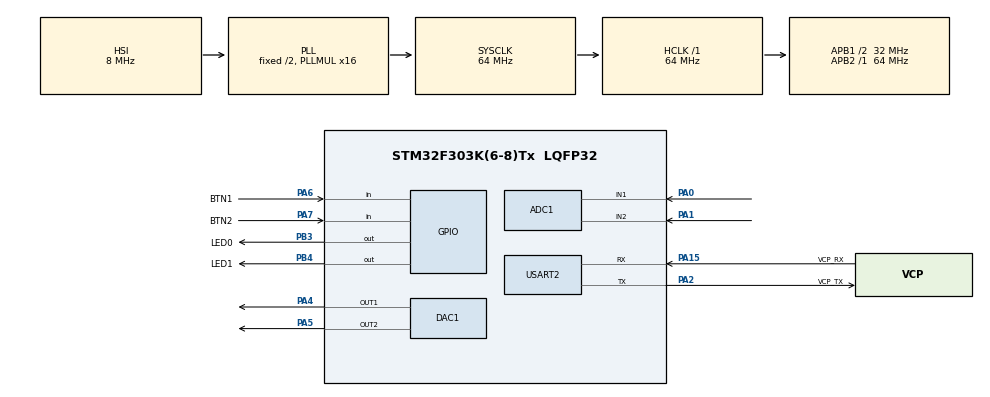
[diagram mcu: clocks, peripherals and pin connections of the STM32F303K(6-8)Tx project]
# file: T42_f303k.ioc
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ADC1.Channel-0\#ChannelRegularConversion=ADC_CHANNEL_1
ADC1.Channel-1\#ChannelRegularConversion=ADC_CHANNEL_2
ADC1.ClockPrescaler=ADC_CLOCK_SYNC_PCLK_DIV4
ADC1.ContinuousConvMode=DISABLE
ADC1.DMAContinuousRequests=ENABLE
ADC1.EOCSelection=ADC_EOC_SEQ_CONV
ADC1.ExternalTrigConv=ADC_EXTERNALTRIGCONV_T6_TRGO
ADC1.NbrOfConversion=2
ADC1.NbrOfConversionFlag=1
ADC1.Offset-0\#ChannelRegularConversion=0
ADC1.Offset-1\#ChannelRegularConversion=0
ADC1.OffsetNumber-0\#ChannelRegularConversion=ADC_OFFSET_NONE
ADC1.OffsetNumber-1\#ChannelRegularConversion=ADC_OFFSET_NONE
ADC1.Rank-0\#ChannelRegularConversion=1
ADC1.Rank-1\#ChannelRegularConversion=2
ADC1.SamplingTime-0\#ChannelRegularConversion=ADC_SAMPLETIME_61CYCLES_5
ADC1.SamplingTime-1\#ChannelRegularConversion=ADC_SAMPLETIME_61CYCLES_5
ADC1.master=1
DAC1.DAC_Trigger=DAC_TRIGGER_T2_TRGO
DAC1.DAC_Trigger2=DAC_TRIGGER_T2_TRGO
Dma.ADC1.0.Direction=DMA_PERIPH_TO_MEMORY
Dma.ADC1.0.Instance=DMA1_Channel1
Dma.ADC1.0.MemDataAlignment=DMA_MDATAALIGN_WORD
Dma.ADC1.0.MemInc=DMA_MINC_ENABLE
Dma.ADC1.0.Mode=DMA_CIRCULAR
Dma.ADC1.0.PeriphDataAlignment=DMA_PDATAALIGN_WORD
Dma.ADC1.0.PeriphInc=DMA_PINC_DISABLE
Dma.ADC1.0.Priority=DMA_PRIORITY_LOW
Dma.DAC1_CH1.1.Direction=DMA_MEMORY_TO_PERIPH
Dma.DAC1_CH1.1.Instance=DMA1_Channel3
Dma.DAC1_CH1.1.MemDataAlignment=DMA_MDATAALIGN_HALFWORD
Dma.DAC1_CH1.1.MemInc=DMA_MINC_ENABLE
Dma.DAC1_CH1.1.Mode=DMA_CIRCULAR
Dma.DAC1_CH1.1.PeriphDataAlignment=DMA_PDATAALIGN_WORD
Dma.DAC1_CH1.1.PeriphInc=DMA_PINC_DISABLE
Dma.DAC1_CH1.1.Priority=DMA_PRIORITY_MEDIUM
Dma.DAC1_CH2.2.Direction=DMA_MEMORY_TO_PERIPH
Dma.DAC1_CH2.2.Instance=DMA1_Channel4
Dma.DAC1_CH2.2.MemDataAlignment=DMA_MDATAALIGN_HALFWORD
Dma.DAC1_CH2.2.MemInc=DMA_MINC_ENABLE
Dma.DAC1_CH2.2.Mode=DMA_CIRCULAR
Dma.DAC1_CH2.2.PeriphDataAlignment=DMA_PDATAALIGN_WORD
Dma.DAC1_CH2.2.PeriphInc=DMA_PINC_DISABLE
Dma.DAC1_CH2.2.Priority=DMA_PRIORITY_MEDIUM
Dma.Request0=ADC1
Dma.Request1=DAC1_CH1
Dma.Request2=DAC1_CH2
Mcu.Family=STM32F3
Mcu.Name=STM32F303K(6-8)Tx
Mcu.Package=LQFP32
NVIC.DMA1_Channel1_IRQn=true\:4\:0\:true\:false\:true\:false\:true\:true
NVIC.DMA1_Channel3_IRQn=true\:0\:0\:false\:false\:true\:false\:true\:true
NVIC.DMA1_Channel4_IRQn=true\:0\:0\:false\:false\:true\:false\:true\:true
NVIC.PriorityGroup=NVIC_PRIORITYGROUP_4
NVIC.TIM2_IRQn=true\:0\:0\:false\:false\:true\:true\:true\:true
NVIC.TIM6_DAC1_IRQn=true\:7\:0\:true\:false\:true\:true\:true\:true
NVIC.TIM7_DAC2_IRQn=true\:11\:0\:true\:false\:true\:true\:true\:true
PA0.Mode=IN1-Single-Ended
PA0.Signal=ADC1_IN1
PA1.Mode=IN2-Single-Ended
PA1.Signal=ADC1_IN2
PA13.GPIO_Label=SWDIO
PA13.Mode=Serial_Wire
PA13.Signal=SYS_JTMS-SWDIO
PA14.GPIO_Label=SWCLK
PA14.Mode=Serial_Wire
PA14.Signal=SYS_JTCK-SWCLK
PA15.GPIO_Label=VCP_RX
PA15.Mode=Asynchronous
PA15.Signal=USART2_RX
PA2.GPIO_Label=VCP_TX
PA2.Mode=Asynchronous
PA2.Signal=USART2_TX
PA4.Signal=COMP_DAC11_group
PA5.Signal=COMP_DAC12_group
PA6.GPIO_Label=BTN1
PA6.GPIO_PuPd=GPIO_PULLUP
PA6.Signal=GPIO_Input
PA7.GPIO_Label=BTN2
PA7.GPIO_PuPd=GPIO_PULLUP
PA7.Signal=GPIO_Input
PB3.GPIO_Label=LED0
PB3.Signal=GPIO_Output
PB4.GPIO_Label=LED1
PB4.Signal=GPIO_Output
PF0\ /\ OSC_IN.GPIO_Label=MCO
PF0\ /\ OSC_IN.Mode=HSE-External-Clock-Source
PF0\ /\ OSC_IN.Signal=RCC_OSC_IN
ProjectManager.HeapSize=0x200
ProjectManager.StackSize=0x400
ProjectManager.TargetToolchain=STM32CubeIDE
RCC.AHBFreq_Value=64000000
RCC.APB1CLKDivider=RCC_HCLK_DIV2
RCC.APB1Freq_Value=32000000
RCC.APB1TimFreq_Value=64000000
RCC.APB2Freq_Value=64000000
RCC.APB2TimFreq_Value=64000000
RCC.CortexFreq_Value=64000000
RCC.HCLKFreq_Value=64000000
RCC.HSE_VALUE=8000000
RCC.HSI_VALUE=8000000
RCC.PLLMUL=RCC_PLL_MUL16
RCC.RCC_PLLsource_Clock_Source_FROM_HSE=RCC_HSE_PREDIV_DIV2
RCC.SYSCLKFreq_VALUE=64000000
RCC.SYSCLKSourceVirtual=RCC_SYSCLKSOURCE_PLLCLK
SH.COMP_DAC11_group.0=DAC1_OUT1,DAC_OUT1
SH.COMP_DAC12_group.0=DAC1_OUT2,DAC_OUT2
TIM2.Period=64
TIM2.Prescaler=1
TIM2.TIM_MasterOutputTrigger=TIM_TRGO_UPDATE
TIM3.Period=4096
TIM6.Period=600
TIM6.Prescaler=319
TIM6.TIM_MasterOutputTrigger=TIM_TRGO_UPDATE
TIM7.Period=600
TIM7.Prescaler=319 
USART2.StopBits=STOPBITS_1
USART2.VirtualMode-Asynchronous=VM_ASYNC
VP_TIM2_VS_ClockSourceINT.Mode=Internal
VP_TIM3_VS_ClockSourceITR.Mode=TriggerSource_ITR0
VP_TIM3_VS_ControllerModeTrigger.Mode=Trigger Mode
VP_TIM6_VS_ClockSourceINT.Mode=Enable_Timer
VP_TIM7_VS_ClockSourceINT.Mode=Enable_Timer
board=NUCLEO-F303K8

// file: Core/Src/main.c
/* USER CODE BEGIN Header */
/**
  ******************************************************************************
  * @file           : main.c
  * @brief          : Main program body
  ******************************************************************************
  * @attention
  *
  * Copyright (c) 2026 STMicroelectronics.
  * All rights reserved.
  *
  * This software is licensed under terms that can be found in the LICENSE file
  * in the root directory of this software component.
  * If no LICENSE file comes with this software, it is provided AS-IS.
  *
  ******************************************************************************
  */
/* USER CODE END Header */
#include "main.h"

/* USER CODE BEGIN Includes */
#include "t42.h"
/* USER CODE END Includes */

ADC_HandleTypeDef hadc1;
DMA_HandleTypeDef hdma_adc1;

DAC_HandleTypeDef hdac1;
DMA_HandleTypeDef hdma_dac1_ch1;
DMA_HandleTypeDef hdma_dac1_ch2;

TIM_HandleTypeDef htim2;
TIM_HandleTypeDef htim3;
TIM_HandleTypeDef htim6;
TIM_HandleTypeDef htim7;

UART_HandleTypeDef huart2;

void SystemClock_Config(void);
static void MX_GPIO_Init(void);
static void MX_DMA_Init(void);
static void MX_USART2_UART_Init(void);
static void MX_ADC1_Init(void);
static void MX_DAC1_Init(void);
static void MX_TIM2_Init(void);
static void MX_TIM3_Init(void);
static void MX_TIM6_Init(void);
static void MX_TIM7_Init(void);

int main(void)
{

  /* MCU Configuration--------------------------------------------------------*/

  /* Reset of all peripherals, Initializes the Flash interface and the Systick. */
  HAL_Init();

  /* Configure the system clock */
  SystemClock_Config();

  /* Initialize all configured peripherals */
  MX_GPIO_Init();
  MX_DMA_Init();
  MX_USART2_UART_Init();
  MX_ADC1_Init();
  MX_DAC1_Init();
  MX_TIM2_Init();
  MX_TIM3_Init();
  MX_TIM6_Init();
  MX_TIM7_Init();
  /* USER CODE BEGIN 2 */
  setupGame();
  /* USER CODE END 2 */

  /* Infinite loop */
  /* USER CODE BEGIN WHILE */
  while (1)
  {
	  updateGame();
    /* USER CODE END WHILE */

  }
}

void SystemClock_Config(void)
{
  RCC_OscInitTypeDef RCC_OscInitStruct = {0};
  RCC_ClkInitTypeDef RCC_ClkInitStruct = {0};

  /** Initializes the RCC Oscillators according to the specified parameters
  * in the RCC_OscInitTypeDef structure.
  */
  RCC_OscInitStruct.OscillatorType = RCC_OSCILLATORTYPE_HSI;
  RCC_OscInitStruct.HSIState = RCC_HSI_ON;
  RCC_OscInitStruct.HSICalibrationValue = RCC_HSICALIBRATION_DEFAULT;
  RCC_OscInitStruct.PLL.PLLState = RCC_PLL_ON;
  RCC_OscInitStruct.PLL.PLLSource = RCC_PLLSOURCE_HSI;
  RCC_OscInitStruct.PLL.PLLMUL = RCC_PLL_MUL16;
  if (HAL_RCC_OscConfig(&RCC_OscInitStruct) != HAL_OK)
  {
    Error_Handler();
  }

  /** Initializes the CPU, AHB and APB buses clocks
  */
  RCC_ClkInitStruct.ClockType = RCC_CLOCKTYPE_HCLK|RCC_CLOCKTYPE_SYSCLK
                              |RCC_CLOCKTYPE_PCLK1|RCC_CLOCKTYPE_PCLK2;
  RCC_ClkInitStruct.SYSCLKSource = RCC_SYSCLKSOURCE_PLLCLK;
  RCC_ClkInitStruct.AHBCLKDivider = RCC_SYSCLK_DIV1;
  RCC_ClkInitStruct.APB1CLKDivider = RCC_HCLK_DIV2;
  RCC_ClkInitStruct.APB2CLKDivider = RCC_HCLK_DIV1;

  if (HAL_RCC_ClockConfig(&RCC_ClkInitStruct, FLASH_LATENCY_2) != HAL_OK)
  {
    Error_Handler();
  }
}

static void MX_ADC1_Init(void)
{

  ADC_MultiModeTypeDef multimode = {0};
  ADC_ChannelConfTypeDef sConfig = {0};

  /** Common config
  */
  hadc1.Instance = ADC1;
  hadc1.Init.ClockPrescaler = ADC_CLOCK_SYNC_PCLK_DIV4;
  hadc1.Init.Resolution = ADC_RESOLUTION_12B;
  hadc1.Init.ScanConvMode = ADC_SCAN_ENABLE;
  hadc1.Init.ContinuousConvMode = DISABLE;
  hadc1.Init.DiscontinuousConvMode = DISABLE;
  hadc1.Init.ExternalTrigConvEdge = ADC_EXTERNALTRIGCONVEDGE_RISING;
  hadc1.Init.ExternalTrigConv = ADC_EXTERNALTRIGCONV_T6_TRGO;
  hadc1.Init.DataAlign = ADC_DATAALIGN_RIGHT;
  hadc1.Init.NbrOfConversion = 2;
  hadc1.Init.DMAContinuousRequests = ENABLE;
  hadc1.Init.EOCSelection = ADC_EOC_SEQ_CONV;
  hadc1.Init.LowPowerAutoWait = DISABLE;
  hadc1.Init.Overrun = ADC_OVR_DATA_OVERWRITTEN;
  if (HAL_ADC_Init(&hadc1) != HAL_OK)
  {
    Error_Handler();
  }

  /** Configure the ADC multi-mode
  */
  multimode.Mode = ADC_MODE_INDEPENDENT;
  if (HAL_ADCEx_MultiModeConfigChannel(&hadc1, &multimode) != HAL_OK)
  {
    Error_Handler();
  }

  /** Configure Regular Channel
  */
  sConfig.Channel = ADC_CHANNEL_1;
  sConfig.Rank = ADC_REGULAR_RANK_1;
  sConfig.SingleDiff = ADC_SINGLE_ENDED;
  sConfig.SamplingTime = ADC_SAMPLETIME_61CYCLES_5;
  sConfig.OffsetNumber = ADC_OFFSET_NONE;
  sConfig.Offset = 0;
  if (HAL_ADC_ConfigChannel(&hadc1, &sConfig) != HAL_OK)
  {
    Error_Handler();
  }

  /** Configure Regular Channel
  */
  sConfig.Channel = ADC_CHANNEL_2;
  sConfig.Rank = ADC_REGULAR_RANK_2;
  if (HAL_ADC_ConfigChannel(&hadc1, &sConfig) != HAL_OK)
  {
    Error_Handler();
  }

}

static void MX_DAC1_Init(void)
{

  DAC_ChannelConfTypeDef sConfig = {0};

  /** DAC Initialization
  */
  hdac1.Instance = DAC1;
  if (HAL_DAC_Init(&hdac1) != HAL_OK)
  {
    Error_Handler();
  }

  /** DAC channel OUT1 config
  */
  sConfig.DAC_Trigger = DAC_TRIGGER_T2_TRGO;
  sConfig.DAC_OutputBuffer = DAC_OUTPUTBUFFER_ENABLE;
  if (HAL_DAC_ConfigChannel(&hdac1, &sConfig, DAC_CHANNEL_1) != HAL_OK)
  {
    Error_Handler();
  }

  /** DAC channel OUT2 config
  */
  sConfig.DAC_OutputSwitch = DAC_OUTPUTSWITCH_ENABLE;
  if (HAL_DAC_ConfigChannel(&hdac1, &sConfig, DAC_CHANNEL_2) != HAL_OK)
  {
    Error_Handler();
  }

}

static void MX_TIM2_Init(void)
{

  TIM_ClockConfigTypeDef sClockSourceConfig = {0};
  TIM_MasterConfigTypeDef sMasterConfig = {0};

  htim2.Instance = TIM2;
  htim2.Init.Prescaler = 1;
  htim2.Init.CounterMode = TIM_COUNTERMODE_UP;
  htim2.Init.Period = 64;
  htim2.Init.ClockDivision = TIM_CLOCKDIVISION_DIV1;
  htim2.Init.AutoReloadPreload = TIM_AUTORELOAD_PRELOAD_DISABLE;
  if (HAL_TIM_Base_Init(&htim2) != HAL_OK)
  {
    Error_Handler();
  }
  sClockSourceConfig.ClockSource = TIM_CLOCKSOURCE_INTERNAL;
  if (HAL_TIM_ConfigClockSource(&htim2, &sClockSourceConfig) != HAL_OK)
  {
    Error_Handler();
  }
  sMasterConfig.MasterOutputTrigger = TIM_TRGO_UPDATE;
  sMasterConfig.MasterSlaveMode = TIM_MASTERSLAVEMODE_DISABLE;
  if (HAL_TIMEx_MasterConfigSynchronization(&htim2, &sMasterConfig) != HAL_OK)
  {
    Error_Handler();
  }

}

static void MX_TIM3_Init(void)
{

  TIM_SlaveConfigTypeDef sSlaveConfig = {0};
  TIM_MasterConfigTypeDef sMasterConfig = {0};

  htim3.Instance = TIM3;
  htim3.Init.Prescaler = 0;
  htim3.Init.CounterMode = TIM_COUNTERMODE_UP;
  htim3.Init.Period = 4096;
  htim3.Init.ClockDivision = TIM_CLOCKDIVISION_DIV1;
  htim3.Init.AutoReloadPreload = TIM_AUTORELOAD_PRELOAD_DISABLE;
  if (HAL_TIM_Base_Init(&htim3) != HAL_OK)
  {
    Error_Handler();
  }
  sSlaveConfig.SlaveMode = TIM_SLAVEMODE_TRIGGER;
  sSlaveConfig.InputTrigger = TIM_TS_ITR0;
  if (HAL_TIM_SlaveConfigSynchro(&htim3, &sSlaveConfig) != HAL_OK)
  {
    Error_Handler();
  }
  sMasterConfig.MasterOutputTrigger = TIM_TRGO_RESET;
  sMasterConfig.MasterSlaveMode = TIM_MASTERSLAVEMODE_DISABLE;
  if (HAL_TIMEx_MasterConfigSynchronization(&htim3, &sMasterConfig) != HAL_OK)
  {
    Error_Handler();
  }

}

static void MX_TIM6_Init(void)
{

  TIM_MasterConfigTypeDef sMasterConfig = {0};

  htim6.Instance = TIM6;
  htim6.Init.Prescaler = 319;
  htim6.Init.CounterMode = TIM_COUNTERMODE_UP;
  htim6.Init.Period = 600;
  htim6.Init.AutoReloadPreload = TIM_AUTORELOAD_PRELOAD_DISABLE;
  if (HAL_TIM_Base_Init(&htim6) != HAL_OK)
  {
    Error_Handler();
  }
  sMasterConfig.MasterOutputTrigger = TIM_TRGO_UPDATE;
  sMasterConfig.MasterSlaveMode = TIM_MASTERSLAVEMODE_DISABLE;
  if (HAL_TIMEx_MasterConfigSynchronization(&htim6, &sMasterConfig) != HAL_OK)
  {
    Error_Handler();
  }

}

static void MX_TIM7_Init(void)
{

  TIM_MasterConfigTypeDef sMasterConfig = {0};

  htim7.Instance = TIM7;
  htim7.Init.Prescaler = 319 ;
  htim7.Init.CounterMode = TIM_COUNTERMODE_UP;
  htim7.Init.Period = 600;
  htim7.Init.AutoReloadPreload = TIM_AUTORELOAD_PRELOAD_DISABLE;
  if (HAL_TIM_Base_Init(&htim7) != HAL_OK)
  {
    Error_Handler();
  }
  sMasterConfig.MasterOutputTrigger = TIM_TRGO_RESET;
  sMasterConfig.MasterSlaveMode = TIM_MASTERSLAVEMODE_DISABLE;
  if (HAL_TIMEx_MasterConfigSynchronization(&htim7, &sMasterConfig) != HAL_OK)
  {
    Error_Handler();
  }

}

static void MX_USART2_UART_Init(void)
{

  huart2.Instance = USART2;
  huart2.Init.BaudRate = 38400;
  huart2.Init.WordLength = UART_WORDLENGTH_8B;
  huart2.Init.StopBits = UART_STOPBITS_1;
  huart2.Init.Parity = UART_PARITY_NONE;
  huart2.Init.Mode = UART_MODE_TX_RX;
  huart2.Init.HwFlowCtl = UART_HWCONTROL_NONE;
  huart2.Init.OverSampling = UART_OVERSAMPLING_16;
  huart2.Init.OneBitSampling = UART_ONE_BIT_SAMPLE_DISABLE;
  huart2.AdvancedInit.AdvFeatureInit = UART_ADVFEATURE_NO_INIT;
  if (HAL_UART_Init(&huart2) != HAL_OK)
  {
    Error_Handler();
  }

}

static void MX_DMA_Init(void)
{

  /* DMA controller clock enable */
  __HAL_RCC_DMA1_CLK_ENABLE();

  /* DMA interrupt init */
  /* DMA1_Channel1_IRQn interrupt configuration */
  HAL_NVIC_SetPriority(DMA1_Channel1_IRQn, 4, 0);
  HAL_NVIC_EnableIRQ(DMA1_Channel1_IRQn);
  /* DMA1_Channel3_IRQn interrupt configuration */
  HAL_NVIC_SetPriority(DMA1_Channel3_IRQn, 0, 0);
  HAL_NVIC_EnableIRQ(DMA1_Channel3_IRQn);
  /* DMA1_Channel4_IRQn interrupt configuration */
  HAL_NVIC_SetPriority(DMA1_Channel4_IRQn, 0, 0);
  HAL_NVIC_EnableIRQ(DMA1_Channel4_IRQn);

}

static void MX_GPIO_Init(void)
{
  GPIO_InitTypeDef GPIO_InitStruct = {0};

  /* GPIO Ports Clock Enable */
  __HAL_RCC_GPIOF_CLK_ENABLE();
  __HAL_RCC_GPIOA_CLK_ENABLE();
  __HAL_RCC_GPIOB_CLK_ENABLE();

  /*Configure GPIO pin Output Level */
  HAL_GPIO_WritePin(GPIOB, LED0_Pin|LED1_Pin, GPIO_PIN_RESET);

  /*Configure GPIO pins : BTN1_Pin BTN2_Pin */
  GPIO_InitStruct.Pin = BTN1_Pin|BTN2_Pin;
  GPIO_InitStruct.Mode = GPIO_MODE_INPUT;
  GPIO_InitStruct.Pull = GPIO_PULLUP;
  HAL_GPIO_Init(GPIOA, &GPIO_InitStruct);

  /*Configure GPIO pins : LED0_Pin LED1_Pin */
  GPIO_InitStruct.Pin = LED0_Pin|LED1_Pin;
  GPIO_InitStruct.Mode = GPIO_MODE_OUTPUT_PP;
  GPIO_InitStruct.Pull = GPIO_NOPULL;
  GPIO_InitStruct.Speed = GPIO_SPEED_FREQ_LOW;
  HAL_GPIO_Init(GPIOB, &GPIO_InitStruct);

}

void Error_Handler(void)
{
  __disable_irq();
  while (1)
  {
  }
}
